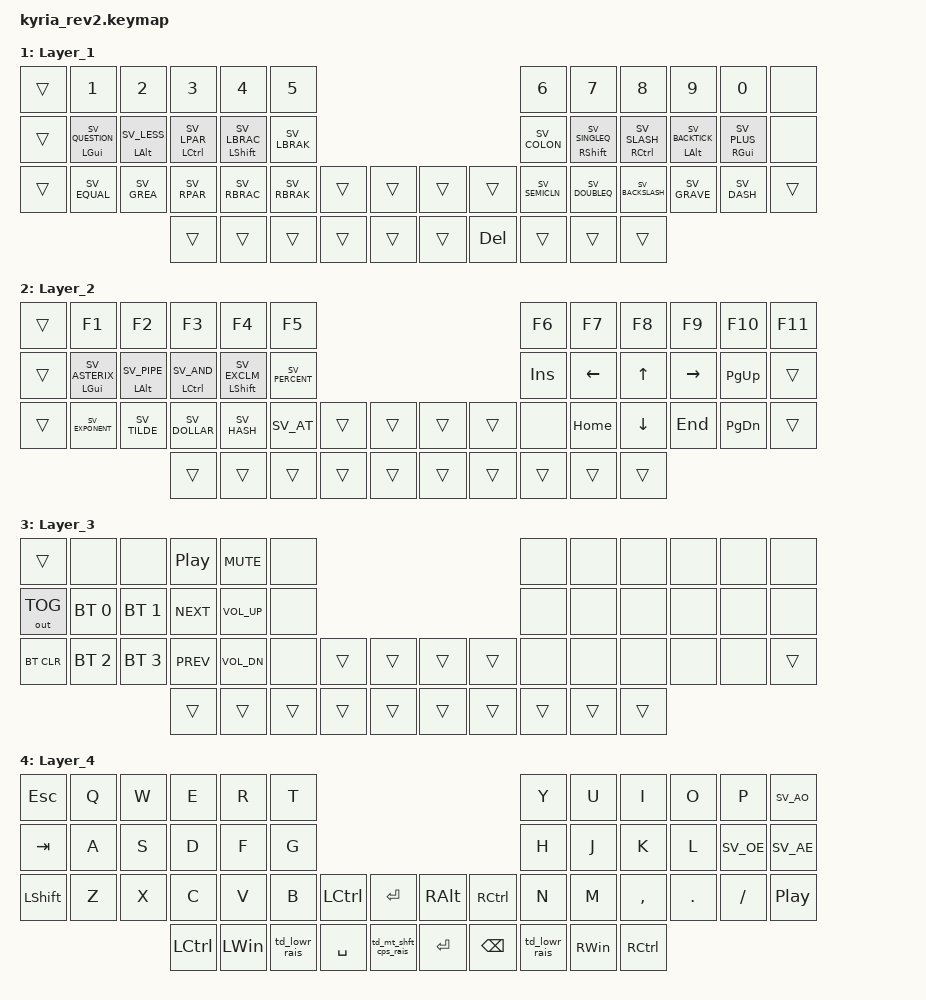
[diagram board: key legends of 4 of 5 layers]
// ################################################################
// ! This keymap is made to work with the SWEDISH keyboard layout !
// ################################################################

#include <behaviors.dtsi>
#include <dt-bindings/zmk/keys.h>
#include <dt-bindings/zmk/outputs.h>
#include <dt-bindings/zmk/rgb.h>
#include <dt-bindings/zmk/bt.h>
#include <dt-bindings/zmk/ext_power.h>
#include <dt-bindings/zmk/modifiers.h>

// (
#define SV_LPAR LS(N8)
// )
#define SV_RPAR LS(N9)
// {
#define SV_LBRAC RA(N7)
// }
#define SV_RBRAC RA(N0)
// [
#define SV_LBRAK RA(N8)
// ]
#define SV_RBRAK RA(N9)
// +
#define SV_PLUS MINUS
// ?
#define SV_QUESTION LS(MINUS)
// å
#define SV_AO LEFT_BRACKET
// ä
#define SV_AE SQT
// ö
#define SV_OE SEMICOLON
// '
#define SV_SINGLEQ BACKSLASH
// "
#define SV_DOUBLEQ LS(N2)
// <
#define SV_LESS NON_US_BACKSLASH
// >
#define SV_GREA LS(NON_US_BACKSLASH)
// /
#define SV_SLASH LS(N7)
// Backslash
#define SV_BACKSLASH RA(MINUS)
// @
#define SV_AT RA(N2)
// |
#define SV_PIPE RA(NON_US_BACKSLASH)
// =
#define SV_EQUAL LS(N0)
// *
#define SV_ASTERIX LS(BACKSLASH)
// $
#define SV_DOLLAR RA(N4)
// `
#define SV_BACKTICK LS(EQUAL)
// ^
#define SV_EXPONENT LS(RIGHT_BRACKET)
// ~
#define SV_TILDE RA(RIGHT_BRACKET)
// §
#define SV_PARAGRAPH GRAVE
// ´
#define SV_GRAVE EQUAL
// :
#define SV_COLON LS(DOT)
// ;
#define SV_SEMICLN LS(COMMA)
// -
#define SV_DASH SLASH
// &
#define SV_AND LS(N6)
// !
#define SV_EXCLM LS(N1)
// %
#define SV_PERCENT LS(N5)
// #
#define SV_HASH LS(N3)

/ {
    combos {
        compatible = "zmk,combos";

        combo_layer_2 {
            timeout-ms = <100>;
            bindings = <&mo 2>;
            key-positions = <42 47>;
        };
    };

    behaviors {
        hm: homerow_mods {
            compatible = "zmk,behavior-hold-tap";
            label = "homerow mods";
            #binding-cells = <2>;
            tapping_term_ms = <170>;
            flavor = "tap-preferred";
            bindings = <&kp>, <&kp>;
        };

        td_mt_shft_cps_rais: td_mt_shft_cps_rais {
            compatible = "zmk,behavior-tap-dance";
            label = "shift caps raise";
            #binding-cells = <0>;
            tapping-term-ms = <200>;
            bindings = <&mt LSHIFT CAPSLOCK>, <&mo 2>;
        };

        td_lowr_rais: td_lowr_rais {
            compatible = "zmk,behavior-tap-dance";
            label = "lower raise";
            #binding-cells = <0>;
            tapping-term-ms = <200>;
            bindings = <&mo 1>, <&mo 2>;
        };

        mm_n2_at: mm_n2_at {
            compatible = "zmk,behavior-mod-morph";
            label = "mm_n2_at";
            #binding-cells = <0>;
            bindings = <&kp N2>, <&kp SV_AT>;
            mods = <(MOD_LSFT|MOD_RSFT)>;
        };

        mm_n4_dolr: mm_n4_dolr {
            compatible = "zmk,behavior-mod-morph";
            label = "mm_n4_dolr";
            #binding-cells = <0>;
            bindings = <&kp N4>, <&kp SV_DOLLAR>;
            mods = <(MOD_LSFT|MOD_RSFT)>;
        };

        mm_n7_bcktik: mm_n7_bcktik {
            compatible = "zmk,behavior-mod-morph";
            label = "mm_n7_bcktik";
            #binding-cells = <0>;
            bindings = <&kp N7>, <&kp SV_BACKTICK>;
            mods = <(MOD_LSFT|MOD_RSFT)>;
            keep-mods = <(MOD_LSFT|MOD_RSFT)>;
        };

        mm_n8_exp: mm_n8_exp {
            compatible = "zmk,behavior-mod-morph";
            label = "mm_n8_exp";
            #binding-cells = <0>;
            bindings = <&kp N8>, <&kp SV_EXPONENT>;
            mods = <(MOD_LSFT|MOD_RSFT)>;
            keep-mods = <(MOD_LSFT|MOD_RSFT)>;
        };

        mm_n9_tlde: mm_n9_tlde {
            compatible = "zmk,behavior-mod-morph";
            label = "mm_n9_tlde";
            #binding-cells = <0>;
            bindings = <&kp N9>, <&kp SV_TILDE>;
            mods = <(MOD_LSFT|MOD_RSFT)>;
        };

        mm_n0_pargh: mm_n0_pargh {
            compatible = "zmk,behavior-mod-morph";
            label = "mm_n0_pargh";
            #binding-cells = <0>;
            bindings = <&kp N0>, <&kp SV_PARAGRAPH>;
            mods = <(MOD_LSFT|MOD_RSFT)>;
            keep-mods = <(MOD_LSFT|MOD_RSFT)>;
        };

        mm_sngle_dble: mm_sngle_dble {
            compatible = "zmk,behavior-mod-morph";
            label = "mm_sngle_dble";
            #binding-cells = <0>;
            bindings = <&kp SV_DOUBLEQ>, <&kp SV_SINGLEQ>;
            mods = <(MOD_LSFT|MOD_RSFT)>;
        };

        mm_eql_grve: mm_eql_grve {
            compatible = "zmk,behavior-mod-morph";
            label = "mm_eql_grve";
            #binding-cells = <0>;
            bindings = <&kp SV_EQUAL>, <&kp SV_GRAVE>;
            mods = <(MOD_LSFT|MOD_RSFT)>;
        };

        mm_lpar_pipe: mm_lpar_pipe {
            compatible = "zmk,behavior-mod-morph";
            label = "mm_lpar_pipe";
            #binding-cells = <0>;
            bindings = <&kp SV_LPAR>, <&kp SV_PIPE>;
            mods = <(MOD_LSFT|MOD_RSFT)>;
        };

        mm_lt_astrx: mm_lt_astrx {
            compatible = "zmk,behavior-mod-morph";
            label = "mm_lt_astrx";
            #binding-cells = <0>;
            bindings = <&kp SV_LESS>, <&kp SV_ASTERIX>;
            mods = <(MOD_LSFT|MOD_RSFT)>;
        };

        mm_qstn_plus: mm_qstn_plus {
            compatible = "zmk,behavior-mod-morph";
            label = "mm_qstn_plus";
            #binding-cells = <0>;
            bindings = <&kp SV_QUESTION>, <&kp SV_PLUS>;
            mods = <(MOD_LSFT|MOD_RSFT)>;
        };

        mm_slsh_bkslsh: mm_slsh_bkslsh {
            compatible = "zmk,behavior-mod-morph";
            label = "mm_slsh_bkslsh";
            #binding-cells = <0>;
            bindings = <&kp SV_SLASH>, <&kp SV_BACKSLASH>;
            mods = <(MOD_LSFT|MOD_RSFT)>;
        };
    };

    keymap {
        compatible = "zmk,keymap";

        Layer_0 {
            // -------------------------------------------------------------------------------------------------------------------------
            // | ESC |  Q  |  W  |  E  |    R     |  T  |                                    |  Y  |  U   |  I  |  O  |  P  |  Å  |
            // | TAB |  A  |  S  |  D  |    F     |  G  |                                    |  H  |  J   |  K  |  L  |  Ö  |  Ä  |
            // |     |  Z  |  X  |  C  |    V     |  B  |       |        |  |        |       |  N  |  M   |  ,; |  .: |  -  |     |
            //                   |     | LWIN/ADJ | LOW | SPACE | LSHIFT |  | RETURN | BKSPC | RAI | PLPA |     |
            bindings = <
&kp ESC  &kp Q       &kp W       &kp E        &kp R         &kp T                                                                  &kp Y  &kp U             &kp I         &kp O        &kp P            &kp SV_AO
&kp TAB  &hm LGUI A  &hm LALT S  &hm LCTRL D  &hm LSHIFT F  &kp G                                                                  &kp H  &hm RSHIFT J      &hm RCTRL K   &hm LALT L   &hm RGUI SV_OE   &kp SV_AE
&none    &kp Z       &kp X       &kp C        &kp V         &kp B  &none       &none                    &none      &none           &kp M  &kp COMMA         &kp DOT       &kp SLASH    &none
                                 &none        &td_lwin_adj  &mo 1  &kp SPACE   &td_mt_shft_cps_rais     &kp RET    &kp BACKSPACE   &mo 2  &kp C_PLAY_PAUSE  &none
            >;
        };

        Layer_1 {
            // --------------------------------------------------------------------------------------------
            // |   |     |     |     |     |     |         #            |     |     |     |     |     |   |
            // |   |  1  |  2  |  3  |  4  |  5  |         #            |  6  |  7  |  8  |  9  |  0  |   |
            // |   |  ?  |  <  |  (  |  {  |  [  |         #            |  :  |  '  |  /  |  `  |  +  |   |
            // |   |  =  |  >  |  )  |  }  |  ]  |   |   | # |   |      |  ;  |  "  |  \  |  ´  |  -  |   |
            //                 |     |     |     |   |   | # |   | DEL  |     |     |     |
            bindings = <
&trans  &kp N1                &kp N2            &kp N3             &kp N4               &kp N5                                            &kp N6          &kp N7                 &kp N8              &kp N9                &kp N0            &none
&trans  &hm LGUI SV_QUESTION  &hm LALT SV_LESS  &hm LCTRL SV_LPAR  &hm LSHIFT SV_LBRAC  &kp SV_LBRAK                                      &kp SV_COLON    &hm RSHIFT SV_SINGLEQ  &hm RCTRL SV_SLASH  &hm LALT SV_BACKTICK  &hm RGUI SV_PLUS  &none
&trans  &kp SV_EQUAL          &kp SV_GREA       &kp SV_RPAR        &kp SV_RBRAC         &kp SV_RBRAK  &trans  &trans     &trans  &trans   &kp SV_SEMICLN  &kp SV_DOUBLEQ         &kp SV_BACKSLASH    &kp SV_GRAVE          &kp SV_DASH       &trans
                                                &trans             &trans               &trans        &trans  &trans     &trans  &kp DEL  &trans          &trans                 &trans
            >;
        };

        Layer_2 {
            // -------------------------------------------------------------------------------------------------
            // |   |     |      |     |     |      |         #         |     |      |      |      |      |     |
            // |   | F1  |  F2  | F3  | F4  |  F5  |         #         | F6  |  F7  |  F8  |  F9  | F10  | F11 |
            // |   |  *  | pipe |  &  |  !  |  %   |         #         | INS | LARR | UARR | RARR | PGUP | F12 |
            // |   |  ^  |  ~   |  $  |  #  |  @   |   |   | # |   |   |     | HOME | DARR | END  | PGDN | LAY |
            //                  |     |     | BKSP |   |   | # |   |   |     |      |      |
            bindings = <
&trans  &kp F1               &kp F2            &kp F3            &kp F4               &kp F5                                             &kp F6      &kp F7          &kp F8          &kp F9           &kp F10    &kp F11
&trans  &hm LGUI SV_ASTERIX  &hm LALT SV_PIPE  &hm LCTRL SV_AND  &hm LSHIFT SV_EXCLM  &kp SV_PERCENT                                     &kp INSERT  &kp LEFT_ARROW  &kp UP_ARROW    &kp RIGHT_ARROW  &kp PG_UP  &trans
&trans  &kp SV_EXPONENT      &kp SV_TILDE      &kp SV_DOLLAR     &kp SV_HASH          &kp SV_AT       &trans  &trans     &trans  &trans  &none       &kp HOME        &kp DOWN_ARROW  &kp END          &kp PG_DN  &trans
                                               &trans            &trans               &trans          &trans  &trans     &trans  &trans  &trans      &trans          &trans
            >;
        };

        Layer_3 {
            // ------------------------------------------------------------------------------------------------------------
            // |         |      |      | PLPA | MUTE |     |                           |     |        |         |         |         |     |
            // | OUT TGL | BT 0 | BT 1 | NEXT | VOLU |     |                           |     | LAYOUT | RGB BRI | RGB EFF | RGB TOG |     |
            // | BT CLR  | BT 2 | BT 3 | PREV | VOLD |     |     |     |  |      |     |     |        | RGB BRD | RGB EFR |         |     |
            //                         |      |      |     |     |     |  |      |     |     |        |         |
            bindings = <
&trans        &none         &none         &kp C_PLAY_PAUSE  &kp C_MUTE    &none                                      &none   &none   &none  &none  &none  &none
&out OUT_TOG  &bt BT_SEL 0  &bt BT_SEL 1  &kp C_NEXT        &kp C_VOL_UP  &none                                      &none   &none   &none  &none  &none  &none
&bt BT_CLR    &bt BT_SEL 2  &bt BT_SEL 3  &kp C_PREV        &kp C_VOL_DN  &none   &trans  &trans     &trans  &trans  &none   &none   &none  &none  &none  &trans
                                          &trans            &trans        &trans  &trans  &trans     &trans  &trans  &trans  &trans  &trans
            >;
        };

        Layer_4 {
            // -------------------------------------------------------------------------------------------------------------------------
            // |  ESC  |  Q  |  W  |   E   |  R   |  T  |                                    |  Y  |  U   |   I   |  O  |  P  |   Å   |
            // |  TAB  |  A  |  S  |   D   |  F   |  G  |                                    |  H  |  J   |   K   |  L  |  Ö  |   Ä   |
            // | SHIFT |  Z  |  X  |   C   |  V   |  B  | LCTRL | RETURN |  |  RALT  | RCTRL |  N  |  M   |  ,;   |  .: |  -  | SHIFT |
            //                     | LCTRL | LWIN | L 1 | SPACE | LSHIFT |  | RETURN | BKSPC | L 1 | RWIN | RCTRL |

            bindings = <
&kp ESC     &kp Q   &kp W   &kp E       &kp R      &kp T                                                                           &kp Y           &kp U      &kp I       &kp O     &kp P       &kp SV_AO
&kp TAB     &kp A   &kp S   &kp D       &kp F      &kp G                                                                           &kp H           &kp J      &kp K       &kp L     &kp SV_OE   &kp SV_AE
&kp LSHFT   &kp Z   &kp X   &kp C       &kp V      &kp B           &kp LCTRL   &kp RET                  &kp RALT   &kp RCTRL       &kp N           &kp M      &kp COMMA   &kp DOT   &kp SLASH   &kp C_PLAY_PAUSE
                            &kp LCTRL   &kp LWIN   &td_lowr_rais   &kp SPACE   &td_mt_shft_cps_rais     &kp RET    &kp BACKSPACE   &td_lowr_rais   &kp RWIN   &kp RCTRL
            >;
        };
    };
};
